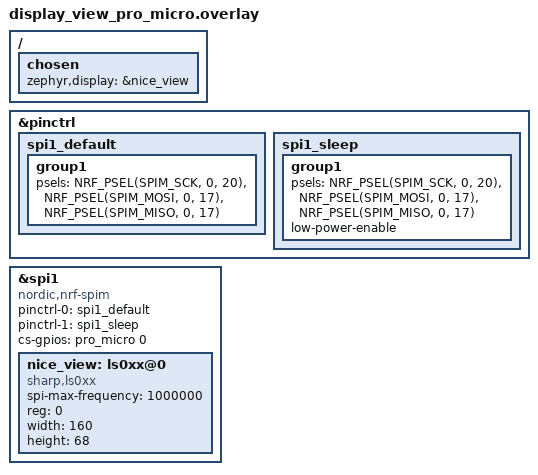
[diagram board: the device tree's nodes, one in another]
/*
 * Copyright (c) 2022 The ZMK Contributors
 *
 * SPDX-License-Identifier: MIT
 */

#include <dt-bindings/pinctrl/nrf-pinctrl.h>

&pinctrl {
    spi1_default: spi1_default {
        group1 {
            psels = <NRF_PSEL(SPIM_SCK, 0, 20)>,
                    <NRF_PSEL(SPIM_MOSI, 0, 17)>,
                    <NRF_PSEL(SPIM_MISO, 0, 17)>;
        };
    };

    spi1_sleep: spi1_sleep {
        group1 {
            psels = <NRF_PSEL(SPIM_SCK, 0, 20)>,
                    <NRF_PSEL(SPIM_MOSI, 0, 17)>,
                    <NRF_PSEL(SPIM_MISO, 0, 17)>;
            low-power-enable;
        };
    };
};

&spi1 {
    status = "okay";
    compatible = "nordic,nrf-spim";
    pinctrl-0 = <&spi1_default>;
    pinctrl-1 = <&spi1_sleep>;
    pinctrl-names = "default", "sleep";
    cs-gpios = <&pro_micro 0 GPIO_ACTIVE_HIGH>;

    nice_view: ls0xx@0 {
        compatible = "sharp,ls0xx";
        spi-max-frequency = <1000000>;
        reg = <0>;
        width = <160>;
        height = <68>;
    };
};

/ {
    chosen {
        zephyr,display = &nice_view;
    };
};
